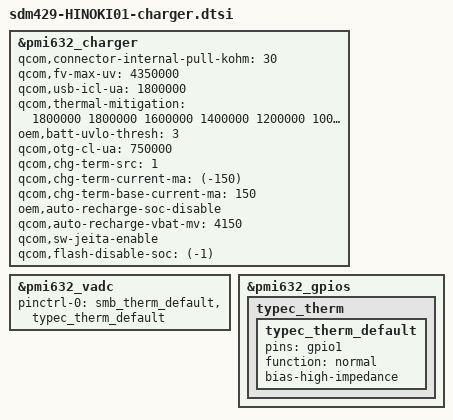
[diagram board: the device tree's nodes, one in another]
/*
 * This software is contributed or developed by KYOCERA Corporation.
 * (C) 2019 KYOCERA Corporation
 *
 * This program is free software; you can redistribute it and/or modify
 * it under the terms of the GNU General Public License version 2 and
 * only version 2 as published by the Free Software Foundation.
 *
 * This program is distributed in the hope that it will be useful,
 * but WITHOUT ANY WARRANTY; without even the implied warranty of
 * MERCHANTABILITY or FITNESS FOR A PARTICULAR PURPOSE.  See the
 * GNU General Public License for more details.
 */

&pmi632_charger {
	qcom,connector-internal-pull-kohm = <30>;
	qcom,fv-max-uv = <4350000>;
	qcom,usb-icl-ua = <1800000>;
	qcom,thermal-mitigation = <1800000 1800000 1600000 1400000 1200000 1000000 800000 600000 400000 200000 0>;
	oem,batt-uvlo-thresh = <3>;
	qcom,otg-cl-ua = <750000>;
	qcom,chg-term-src = <1>;
	qcom,chg-term-current-ma = <(-150)>;
	qcom,chg-term-base-current-ma = <150>;
	oem,auto-recharge-soc-disable;
	qcom,auto-recharge-vbat-mv = <4150>;
	qcom,sw-jeita-enable;
	qcom,flash-disable-soc = <(-1)>;
};

&pmi632_vadc {
	pinctrl-0 = <&smb_therm_default &typec_therm_default>;
};

&pmi632_gpios {
	typec_therm {
		typec_therm_default: typec_therm_default {
			pins = "gpio1";
			function = "normal";
			bias-high-impedance;
		};
	};
};
